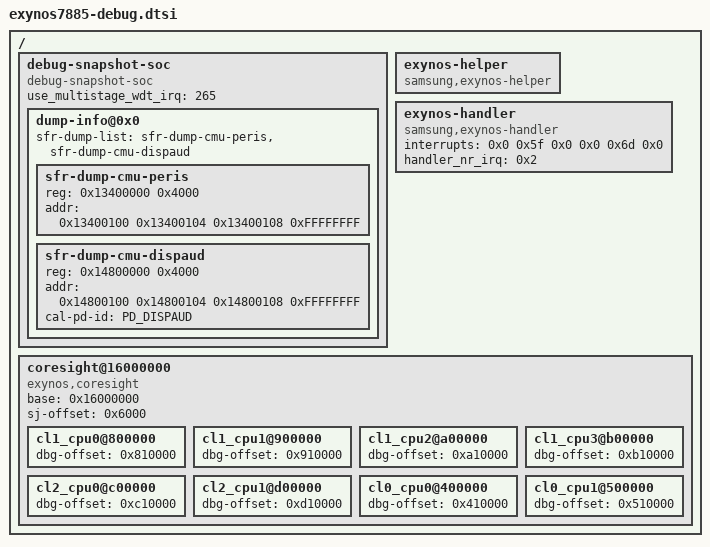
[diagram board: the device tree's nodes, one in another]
/*
 * SAMSUNG EXYNOS7885 SoC device tree source
 *
 * Copyright (c) 2015 Samsung Electronics Co., Ltd.
 *		http://www.samsung.com
 *
 * SAMSUNG EXYNOS8890 SoC device nodes are listed in this file.
 * EXYNOS8890 based board files can include this file and provide
 * values for board specfic bindings.
 *
 * This program is free software; you can redistribute it and/or modify
 * it under the terms of the GNU General Public License version 2 as
 * published by the Free Software Foundation.
 */

/ {
	debug-snapshot-soc {
		/* refer from drivers/soc/samsung/cal-if/exynos7885/pmucal_local_exynos7885.h */
		#define PD_DISPAUD	(0)
		#define PD_MFCMSCL	(1)
		#define PD_ISP		(2)
		#define PD_CAM		(3)
		#define PD_G3D		(4)

		compatible = "debug-snapshot-soc";
		use_multistage_wdt_irq = <265>;

		dump-info@0x0 {
			sfr-dump-list = "sfr-dump-cmu-peris", "sfr-dump-cmu-dispaud";
			#address-cells = <1>;
			#size-cells = <1>;
			sfr-dump-cmu-peris {
				reg = <0x13400000 0x4000>;
				addr = <0x13400100 0x13400104 0x13400108 0xFFFFFFFF>;
			};

			sfr-dump-cmu-dispaud {
				reg = <0x14800000 0x4000>;
				addr = <0x14800100 0x14800104 0x14800108 0xFFFFFFFF>;
				/* input avaiable array. (ex: cal-pd-id = <PD_DPU0 PD_DPU1>;) */
				cal-pd-id = <PD_DISPAUD>;
			};
		};
	};

	exynos-helper {
		compatible = "samsung,exynos-helper";
	};

	exynos-handler {
		compatible = "samsung,exynos-handler";
		interrupts = <0x0 0x5f 0x0 0x0 0x6d 0x0>;
		handler_nr_irq = <0x2>;
	};

	coresight@16000000 {
		compatible = "exynos,coresight";
		base = <0x16000000>;
		sj-offset = <0x6000>;

		cl1_cpu0@800000 {
			device_type = "cs";
			dbg-offset = <0x810000>;
		};

		cl1_cpu1@900000 {
			device_type = "cs";
			dbg-offset = <0x910000>;
		};

		cl1_cpu2@a00000 {
			device_type = "cs";
			dbg-offset = <0xa10000>;
		};

		cl1_cpu3@b00000 {
			device_type = "cs";
			dbg-offset = <0xb10000>;
		};

		cl2_cpu0@c00000 {
			device_type = "cs";
			dbg-offset = <0xc10000>;
		};

		cl2_cpu1@d00000 {
			device_type = "cs";
			dbg-offset = <0xd10000>;
		};

		cl0_cpu0@400000 {
			device_type = "cs";
			dbg-offset = <0x410000>;
		};

		cl0_cpu1@500000 {
			device_type = "cs";
			dbg-offset = <0x510000>;
		};
	};
};
